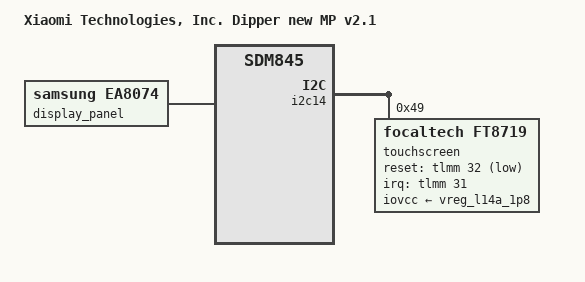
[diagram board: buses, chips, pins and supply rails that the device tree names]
// SPDX-License-Identifier: GPL-2.0
/*
 * SDM845 Xiaomi Mi 8 (dipper) device tree
 *
 * Copyright (c) 2017, The Linux Foundation. All rights reserved.
 * Copyright (C) 2018, XiaoMi, Inc.
 * Copyright (c) 2024, Jacob Hrbek <kreyren@fsfe.org>
 */

/dts-v1/;

#include "sdm845-xiaomi-mi8-common.dtsi"

/ {
	model = "Xiaomi Technologies, Inc. Dipper new MP v2.1";
	compatible = "xiaomi,dipper", "qcom,sdm845-mtp", "qcom,sdm845", "qcom,mtp";

	/* required for bootloader to select correct board */
	// REVIEW(Krey): From https://github.com/LineageOS/android_kernel_xiaomi_sdm845/blob/lineage-21/arch/arm64/boot/dts/qcom/dipper-mp-v2.1.dts#L25
	qcom,board-id = <55 0>;
};

&display_panel {
	compatible = "samsung,ea8074";
	status = "okay";
};

&i2c14 {
	status = "okay";

	touchscreen@49 {
		compatible = "focaltech,ft8719";
		reg = <0x49>;

		interrupts-extended = <&tlmm 31 IRQ_TYPE_EDGE_FALLING>;
		reset-gpios = <&tlmm 32 GPIO_ACTIVE_LOW>;

		iovcc-supply = <&vreg_l14a_1p8>;

		pinctrl-0 = <&ts_int_default &ts_reset_default>;
		pinctrl-1 = <&ts_int_sleep &ts_reset_sleep>;
		pinctrl-names = "default", "sleep";

		touchscreen-size-x = <1080>;
		touchscreen-size-y = <2248>;
	};
};
